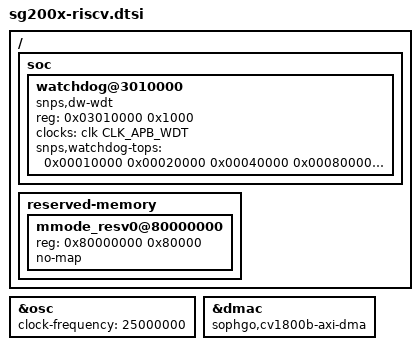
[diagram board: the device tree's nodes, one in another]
// SPDX-License-Identifier: (GPL-2.0 OR MIT)
/*
 * The SG200x C906 view, on any package: the fixes every board needs on top of the
 * kernel's sg2002.dtsi. Included after the board's other layers.
 */

/ {
	/*
	 * SoC reset for userspace `reboot` (the riscv twin of the ARM DTS's
	 * watchdog node, same disease, different firmware path).
	 *
	 * The mainline cv18xx dtsi has no watchdog node, so mainline Linux
	 * registers no restart handler for this SoC beyond SBI SRST. OpenSBI's
	 * generic SRST needs a platform reset driver it does not have for
	 * cv18xx/sg2000, so the ecall returns and machine_restart() spins forever
	 * after "reboot: Restarting system" (bench-proven on the polyglot fip
	 * bring-up, 2026-09-02, the riscv reboot hung until a button press).
	 *
	 * Fix, as on ARM: expose the DesignWare watchdog. dw_wdt (DW_WATCHDOG=y,
	 * set for both cores in modules/sg2k/kernel.nix) registers a restart
	 * handler at priority 128 that programs the shortest timeout in RESET
	 * response mode. The vendor FSBL (both slots of the polyglot BL2) writes
	 * RTC_EN_WDT_RST_REQ (0x050260E0) = 1 in early platform init, so the
	 * timeout propagates to a full SoC reset. Node facts (base, size, clock)
	 * as in the ARM DTS: base 0x03010000 from the vendor cv181x_base.dtsi,
	 * CLK_APB_WDT gates the 25 MHz timer clock, `resets` omitted (optional,
	 * already out of reset).
	 */
	soc {
		watchdog@3010000 {
			compatible = "snps,dw-wdt";
			reg = <0x03010000 0x1000>;
			clocks = <&clk CLK_APB_WDT>;
			/* Use the hardware's standard DesignWare periods: 2^(16+n) cycles. */
			snps,watchdog-tops = <0x00010000 0x00020000 0x00040000 0x00080000
					      0x00100000 0x00200000 0x00400000 0x00800000
					      0x01000000 0x02000000 0x04000000 0x08000000
					      0x10000000 0x20000000 0x40000000 0x80000000>;
		};
	};

	/*
	 * OpenSBI stays resident in M-mode at 0x80000000 and PMP-protects its
	 * own memory from S-mode. Its boot banner states the regions:
	 *
	 *   Domain0 Region01 : 0x80000000-0x8003ffff M: (F,R,X) S/U: ()
	 *   Domain0 Region00 : 0x80040000-0x8005ffff M: (F,R,W) S/U: ()
	 *
	 * So 0x80000000..0x8005ffff (384 KB) is unreachable from Linux.
	 *
	 * OpenSBI normally patches an mmode_resv node into the device tree it
	 * hands onward. The boot chain is OpenSBI -> U-Boot -> a DTB loaded
	 * fresh from the FAT boot partition, so that fixup never reaches the
	 * DTB that Linux receives. Without this node the kernel treats the
	 * firmware memory as free RAM, hands out the page at 0x80000000, and
	 * faults when it zeroes that page (physical 0x80000000 maps to
	 * PAGE_OFFSET_L3, the base of the sv39 linear map).
	 *
	 * Reserve 512 KB, the 384 KB rounded up, to allow room for an OpenSBI
	 * version bump.
	 */
	reserved-memory {
		#address-cells = <1>;
		#size-cells = <1>;
		ranges;

		mmode_resv0@80000000 {
			reg = <0x80000000 0x80000>;
			no-map;
		};
	};
};

&osc {
	clock-frequency = <25000000>;
};

/*
 * DMA controller for SPI3 slave DMA (the board's &spi3 dmas). The base
 * cv180x.dtsi gives it the generic snps,axi-dma-1.01a compatible, which lacks
 * ARG0_AS_CHAN, so dw_axi_dma_of_xlate would take the apb_regs handshake path
 * this SoC never wires up ("apb_regs not initialized"). sophgo,cv1800b-axi-dma
 * sets ARG0_AS_CHAN, so of_xlate uses the channel the dmamux allocated. The
 * dmamux (dma-router@154) lives in the always-on top syscon and is already live.
 */
&dmac {
	compatible = "sophgo,cv1800b-axi-dma";
	status = "okay";
};
